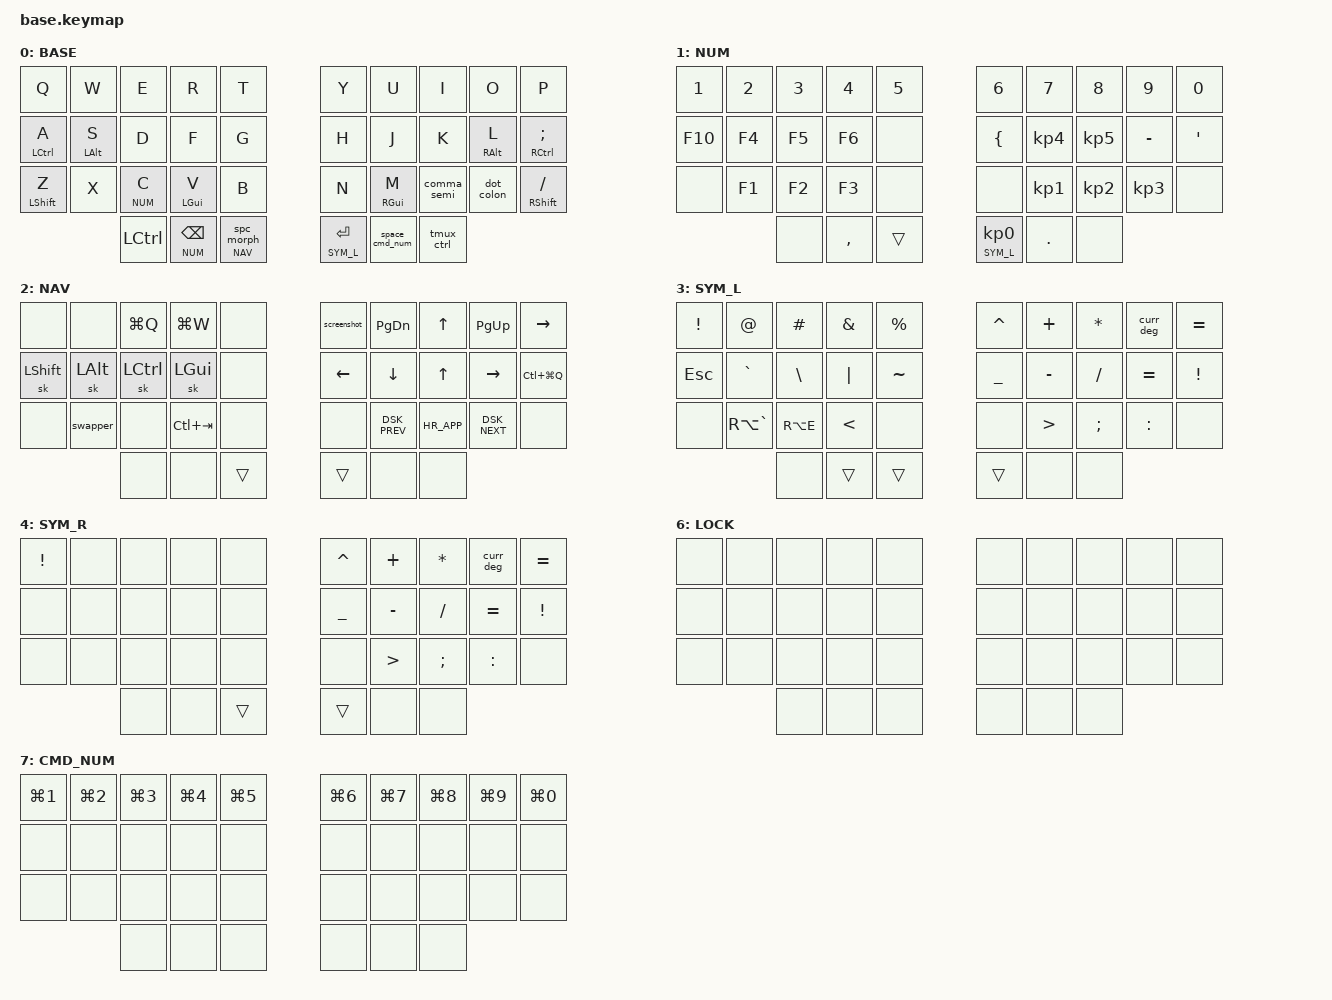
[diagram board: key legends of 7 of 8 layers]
#include <behaviors.dtsi>
#include <dt-bindings/zmk/keys.h>
#include <dt-bindings/zmk/outputs.h>

// ── LAYERS ────────────────────────────────────────────────────────────────────

#define BASE 0
#define NUM 1
#define NAV 2
#define SYM_L 3
#define SYM_R 4
#define ADJ 5
#define LOCKL 6
#define CMD_NUM 7

#define xxx &none
#define ___ &trans

// ── INCLUDES & BLUETOOTH ──────────────────────────────────────────────────────

#include "combos.dtsi"
#if WIRELESS
    #include <dt-bindings/zmk/bt.h>
    #define BTL1  &bt BT_CLR   &bt BT_SEL 2  &bt BT_SEL 1  &bt BT_SEL 0
    #define BTL2  xxx          &bt BT_SEL 4  &bt BT_SEL 3  &out OUT_TOG
#else
    #define BTL1  xxx   xxx   xxx   xxx
    #define BTL2  xxx   xxx   xxx   xxx
#endif

// ── TIMING ────────────────────────────────────────────────────────────────────

#define TAP_TERM_MS 200
#define QUICK_TAP_MS 125

// ── KEY SHORTCUTS ─────────────────────────────────────────────────────────────

#define deg RA(LS(N8))
#define HR_APP LG(LS(SPACE))
#define DSK_PREV LC(LEFT)
#define DSK_NEXT LC(RIGHT)

// ── KEY POSITIONS (for homerow mods) ──────────────────────────────────────────
//  ╭─────────────────────╮ ╭─────────────────────╮
//  │  00  01  02  03  04 │ │  05  06  07  08  09 │
//  │  10  11  12  13  14 │ │  15  16  17  18  19 │
//  │  20  21  22  23  24 │ │  25  26  27  28  29 │
//  ╰───────╮  30  31  32 │ │  33  34  35 ╭───────╯
//          ╰─────────────╯ ╰─────────────╯

#define LEFT_KEYS  0 1 2 3 4 10 11 12 13 14 20 21 22 23 24
#define RIGHT_KEYS 5 6 7 8 9 15 16 17 18 19 25 26 27 28 29
#define THUMBS     30 31 32 33 34 35

// ── GLOBAL BEHAVIOR OVERRIDES ─────────────────────────────────────────────────

&lt {
    flavor = "balanced";
    tapping-term-ms = <TAP_TERM_MS>;
    quick-tap-ms = <QUICK_TAP_MS>;
};

&sk {
    release-after-ms = <1000>;
    quick-release;
};

&sl {
    release-after-ms = <5000>;
};

&caps_word {
    continue-list = <UNDERSCORE MINUS BSPC N1 N2 N3 N4 N5 N6 N7 N8 N9 N0>;
};

// ── MAIN TREE ─────────────────────────────────────────────────────────────────

/ {
    behaviors {

        // ── HOMEROW MODS (timeless) ───────────────────────────────────────────
        // Only trigger hold when the *opposite* hand presses a key,
        // and only if there was an idle gap before the HRM key.

        hml: left_hand_positional_hold_tap {
            compatible = "zmk,behavior-hold-tap";
            label = "LEFT_POSITIONAL_HOLD_TAP";
            #binding-cells = <2>;
            flavor = "balanced";
            tapping-term-ms = <TAP_TERM_MS>;
            quick-tap-ms = <QUICK_TAP_MS>;
            require-prior-idle-ms = <100>;
            bindings = <&kp>, <&kp>;
            hold-trigger-key-positions = <RIGHT_KEYS THUMBS>;
            hold-trigger-on-release;
        };

        hmr: right_hand_positional_hold_tap {
            compatible = "zmk,behavior-hold-tap";
            label = "RIGHT_POSITIONAL_HOLD_TAP";
            #binding-cells = <2>;
            flavor = "balanced";
            tapping-term-ms = <TAP_TERM_MS>;
            quick-tap-ms = <QUICK_TAP_MS>;
            require-prior-idle-ms = <100>;
            bindings = <&kp>, <&kp>;
            hold-trigger-key-positions = <LEFT_KEYS THUMBS>;
            hold-trigger-on-release;
        };

        // ── TAP DANCES ────────────────────────────────────────────────────────

        curr_deg: tap_dance_curr_deg { // $ → € → °
            compatible = "zmk,behavior-tap-dance";
            label = "TAP_DANCE_curr_deg";
            #binding-cells = <0>;
            tapping-term-ms = <TAP_TERM_MS>;
            bindings = <&kp DLLR>, <&kp LA(N5)>, <&kp deg>;
        };
        screenshot: screenshot { // area selector → full-screen
            compatible = "zmk,behavior-tap-dance";
            label = "SCREENSHOT";
            #binding-cells = <0>;
            tapping-term-ms = <TAP_TERM_MS>;
            bindings = <&kp LG(LS(NUMBER_4))>, <&kp LG(LS(NUMBER_3))>;
        };
        tmux_ctrl: tmux_ctrl {
            compatible = "zmk,behavior-tap-dance";
            label = "TMUX_CTRL";
            #binding-cells = <0>;
            tapping-term-ms = <TAP_TERM_MS>;
            bindings = <&kp RCTRL>, <&tmux_num>;
        };
        space_cmd_num: space_cmd_num {
            compatible = "zmk,behavior-tap-dance";
            label = "SPACE_CMD_NUM";
            #binding-cells = <0>;
            tapping-term-ms = <TAP_TERM_MS>;
            bindings = <&kp SPACE>, <&mo CMD_NUM>;
        };

        // ── SMART SPACE (hold: layer | tap: space | shift+tap: ". " + sticky shift) ──

        spc_morph: spc_morph {
            compatible = "zmk,behavior-mod-morph";
            label = "SPC_MORPH";
            #binding-cells = <0>;
            bindings = <&kp SPACE>, <&dot_spc>;
            mods = <(MOD_LSFT)>;
        };
        lt_spc: lt_spc {
            compatible = "zmk,behavior-hold-tap";
            label = "LT_SPC";
            #binding-cells = <2>;
            tapping-term-ms = <TAP_TERM_MS>;
            quick-tap-ms = <QUICK_TAP_MS>;
            flavor = "balanced";
            bindings = <&mo>, <&spc_morph>;
        };

        // ── ALT-TAB SWAPPER (tri-state: Cmd+Tab) ────────────────────────────

        swapper: swapper {
            compatible = "zmk,behavior-tri-state";
            label = "SWAPPER";
            #binding-cells = <0>;
            bindings = <&kt LGUI>, <&kp TAB>, <&kt LGUI>;
            ignored-key-positions = <31>;
        };

        // ── MOD-MORPHS (shift changes symbol) ────────────────────────────────

        dot_colon: dot_colon { // . → :
            compatible = "zmk,behavior-mod-morph";
            label = "DOT_TO_COLON";
            #binding-cells = <0>;
            bindings = <&kp DOT>, <&kp COLON>;
            mods = <(MOD_LSFT|MOD_RSFT)>;
        };
        comma_semi: comma_semi { // , → ;
            compatible = "zmk,behavior-mod-morph";
            label = "COMMA_TO_SEMICOLON";
            #binding-cells = <0>;
            bindings = <&kp COMMA>, <&kp SEMICOLON>;
            mods = <(MOD_LSFT|MOD_RSFT)>;
        };
        single_to_doublequote: single_to_doublequote { // ' → "
            compatible = "zmk,behavior-mod-morph";
            label = "SINGLE_TO_DOUBLEQUOTE";
            #binding-cells = <0>;
            bindings = <&kp SINGLE_QUOTE>, <&kp DOUBLE_QUOTES>;
            mods = <(MOD_LSFT|MOD_RSFT)>;
        };
    };

    // ── MACROS ────────────────────────────────────────────────────────────────

    macros {
        // delete entire line: End → Cmd+Home → Backspace
        del_line: del_line {
            label = "ZMK_DEL_LINE";
            compatible = "zmk,behavior-macro";
            #binding-cells = <0>;
            bindings
                = <&macro_press &kp END>
                , <&macro_press &kp LGUI>
                , <&macro_tap &kp HOME>
                , <&macro_release &kp LGUI>
                , <&macro_tap &kp BSPC>
                ;
        };

        // sentence ending: types ". " then activates sticky shift
        dot_spc: dot_spc {
            label = "ZM_DOT_SPACE";
            compatible = "zmk,behavior-macro";
            #binding-cells = <0>;
            wait-ms = <0>;
            tap-ms = <5>;
            bindings = <&kp DOT &kp SPACE &sk LSHFT>;
        };

        // tmux window selection: send prefix, then enable NUM for one keypress
        tmux_num: tmux_num {
            label = "TMUX_NUM";
            compatible = "zmk,behavior-macro";
            #binding-cells = <0>;
            bindings = <&kp LC(A) &sl NUM>;
        };
    };

    // ── CONDITIONAL LAYERS ────────────────────────────────────────────────────
    // NAV + SYM_L → ADJ (hold both layer thumbs)

    conditional_layers {
        compatible = "zmk,conditional-layers";
        tri_layer {
            if-layers = <NAV SYM_L>;
            then-layer = <ADJ>;
        };
    };

    // ── KEYMAP ────────────────────────────────────────────────────────────────

    keymap {
        compatible = "zmk,keymap";

        default_layer {
            label = "BASE";
            bindings = <
             //╭──────────────┬──────────────┬──────────────┬──────────────┬──────────────╮     ╭──────────────┬──────────────┬──────────────┬──────────────┬──────────────╮
                &kp Q            &kp W          &kp E          &kp R         &kp T                 &kp Y          &kp U          &kp I          &kp O          &kp P
             //├──────────────┼──────────────┼──────────────┼──────────────┼──────────────┤     ├──────────────┼──────────────┼──────────────┼──────────────┼──────────────┤
                &hml LCTRL A    &hml LALT S    &kp D          &kp F           &kp G                 &kp H          &kp J          &kp K          &hmr RALT L  &hmr RCTRL SEMI
             //├──────────────┼──────────────┼──────────────┼──────────────┼──────────────┤     ├──────────────┼──────────────┼──────────────┼──────────────┼──────────────┤
                &hml LSHIFT Z    &kp X          &lt NUM C      &hml LGUI V    &kp B                &kp N            &hmr RGUI M  &comma_semi    &dot_colon     &hmr RSHIFT SLASH
             //╰──────────────┴──────────────┼──────────────┼──────────────┼──────────────┤     ├──────────────┼──────────────┼──────────────┼──────────────┴──────────────╯
                                              &kp LCTRL        &lt NUM BSPC   &lt_spc NAV 0        &lt SYM_L RET    &space_cmd_num &tmux_ctrl
             //                              ╰──────────────┴──────────────┴──────────────╯     ╰──────────────┴──────────────┴──────────────╯
            >;
        };

        num_layer {
            label = "NUM";
            bindings = <
             //╭──────────────┬──────────────┬──────────────┬──────────────┬──────────────╮     ╭──────────────┬──────────────┬──────────────┬──────────────┬──────────────╮
                &kp N1         &kp N2         &kp N3         &kp N4         &kp N5               &kp N6         &kp N7         &kp N8         &kp N9         &kp N0
             //├──────────────┼──────────────┼──────────────┼──────────────┼──────────────┤     ├──────────────┼──────────────┼──────────────┼──────────────┼──────────────┤
                &kp F10        &kp F4         &kp F5         &kp F6         xxx                  &kp LBRC       &kp KP_N4      &kp KP_N5      &kp MINUS      &kp SQT
             //├──────────────┼──────────────┼──────────────┼──────────────┼──────────────┤     ├──────────────┼──────────────┼──────────────┼──────────────┼──────────────┤
                xxx            &kp F1         &kp F2         &kp F3         xxx                  xxx            &kp KP_N1      &kp KP_N2      &kp KP_N3      xxx
             //╰──────────────┴──────────────┼──────────────┼──────────────┼──────────────┤     ├──────────────┼──────────────┼──────────────┼──────────────┴──────────────╯
                                              xxx            &kp COMMA      ___                  &lt SYM_L KP_N0 &kp DOT       xxx
             //                              ╰──────────────┴──────────────┴──────────────╯     ╰──────────────┴──────────────┴──────────────╯
            >;
        };

        nav_layer {
            label = "NAV";
            bindings = <
             //╭──────────────┬──────────────┬──────────────┬──────────────┬──────────────╮     ╭──────────────┬──────────────┬──────────────┬──────────────┬──────────────╮
                xxx            xxx            &kp LG(Q)      &kp LG(W)      xxx                  &screenshot      &kp PG_DN      &kp UP         &kp PG_UP      &kp RIGHT
             //├──────────────┼──────────────┼──────────────┼──────────────┼──────────────┤     ├──────────────┼──────────────┼──────────────┼──────────────┼──────────────┤
                &sk LSHFT      &sk LALT       &sk LCTRL      &sk LGUI       xxx                  &kp LEFT         &kp DOWN        &kp UP       &kp RIGHT      &kp LC(LG(Q))
             //├──────────────┼──────────────┼──────────────┼──────────────┼──────────────┤     ├──────────────┼──────────────┼──────────────┼──────────────┼──────────────┤
                xxx            &swapper       xxx            &kp LC(TAB)    xxx                  xxx              &kp DSK_PREV   &kp HR_APP     &kp DSK_NEXT   xxx
             //╰──────────────┴──────────────┼──────────────┼──────────────┼──────────────┤     ├──────────────┼──────────────┼──────────────┼──────────────┴──────────────╯
                                              xxx            xxx            ___                  ___            xxx            xxx
             //                              ╰──────────────┴──────────────┴──────────────╯     ╰──────────────┴──────────────┴──────────────╯
            >;
        };

        symbols_left { // activated by right thumb — symbols on both hands
            label = "SYM_L";
            bindings = <
             //╭──────────────┬──────────────┬──────────────┬──────────────┬──────────────╮     ╭──────────────┬──────────────┬──────────────┬──────────────┬──────────────╮
                &kp EXCL       &kp AT         &kp HASH       &kp AMPS       &kp PERCENT          &kp CARET      &kp PLUS       &kp ASTRK      &curr_deg      &kp EQUAL
             //├──────────────┼──────────────┼──────────────┼──────────────┼──────────────┤     ├──────────────┼──────────────┼──────────────┼──────────────┼──────────────┤
                &kp ESCAPE     &kp GRAVE      &kp BSLH       &kp PIPE       &kp TILDE            &kp UNDER      &kp MINUS      &kp SLASH      &kp EQUAL      &kp EXCL
             //├──────────────┼──────────────┼──────────────┼──────────────┼──────────────┤     ├──────────────┼──────────────┼──────────────┼──────────────┼──────────────┤
                xxx            &kp RA(GRAVE)  &kp RA(E)      &kp LT         xxx                  xxx            &kp GT         &kp SEMI       &kp COLON      xxx
             //╰──────────────┴──────────────┼──────────────┼──────────────┼──────────────┤     ├──────────────┼──────────────┼──────────────┼──────────────┴──────────────╯
                                              xxx            ___            ___                  ___            xxx            xxx
             //                              ╰──────────────┴──────────────┴──────────────╯     ╰──────────────┴──────────────┴──────────────╯
            >;
        };

        symbols_right { // activated by left thumb — right-hand symbols
            label = "SYM_R";
            bindings = <
             //╭──────────────┬──────────────┬──────────────┬──────────────┬──────────────╮     ╭──────────────┬──────────────┬──────────────┬──────────────┬──────────────╮
                &kp EXCL       xxx            xxx            xxx            xxx                  &kp CARET      &kp PLUS       &kp ASTRK      &curr_deg      &kp EQUAL
             //├──────────────┼──────────────┼──────────────┼──────────────┼──────────────┤     ├──────────────┼──────────────┼──────────────┼──────────────┼──────────────┤
                xxx            xxx            xxx            xxx            xxx                  &kp UNDER      &kp MINUS      &kp SLASH      &kp EQUAL      &kp EXCL
             //├──────────────┼──────────────┼──────────────┼──────────────┼──────────────┤     ├──────────────┼──────────────┼──────────────┼──────────────┼──────────────┤
                xxx            xxx            xxx            xxx            xxx                  xxx            &kp GT         &kp SEMI       &kp COLON      xxx
             //╰──────────────┴──────────────┼──────────────┼──────────────┼──────────────┤     ├──────────────┼──────────────┼──────────────┼──────────────┴──────────────╯
                                              xxx            xxx            ___                  ___            xxx            xxx
             //                              ╰──────────────┴──────────────┴──────────────╯     ╰──────────────┴──────────────┴──────────────╯
            >;
        };

        adj_layer { // tri-layer: SYM_L + SYM_R — system, media, bluetooth
            label = "ADJ";
            bindings = <
             //╭──────────────┬──────────────┬──────────────┬──────────────┬──────────────╮     ╭──────────────┬──────────────┬──────────────┬──────────────┬──────────────╮
                xxx              xxx            xxx            xxx            &bootloader          &bootloader    &kp C_PP       &kp C_NEXT     &kp C_PREV     xxx
             //├──────────────┼──────────────┼──────────────┼──────────────┼──────────────┤     ├──────────────┼──────────────┼──────────────┼──────────────┼──────────────┤
                BTL1                                                        &sys_reset           &sys_reset     &kp C_VOL_DN   &kp C_VOL_UP   &kp C_MUTE     xxx
             //├──────────────┼──────────────┼──────────────┼──────────────┼──────────────┤     ├──────────────┼──────────────┼──────────────┼──────────────┼──────────────┤
                BTL2                                                        xxx                  xxx            &kp C_BRI_DN   &kp C_BRI_UP   xxx            xxx
             //╰──────────────┴──────────────┼──────────────┼──────────────┼──────────────┤     ├──────────────┼──────────────┼──────────────┼──────────────┴──────────────╯
                                              xxx            xxx            xxx                  xxx            xxx            xxx
             //                              ╰──────────────┴──────────────┴──────────────╯     ╰──────────────┴──────────────┴──────────────╯
            >;
        };

        lock_layer {
            label = "LOCK";
            bindings = <
             //╭──────────────┬──────────────┬──────────────┬──────────────┬──────────────╮     ╭──────────────┬──────────────┬──────────────┬──────────────┬──────────────╮
                xxx            xxx            xxx            xxx            xxx                  xxx            xxx            xxx            xxx            xxx
             //├──────────────┼──────────────┼──────────────┼──────────────┼──────────────┤     ├──────────────┼──────────────┼──────────────┼──────────────┼──────────────┤
                xxx            xxx            xxx            xxx            xxx                  xxx            xxx            xxx            xxx            xxx
             //├──────────────┼──────────────┼──────────────┼──────────────┼──────────────┤     ├──────────────┼──────────────┼──────────────┼──────────────┼──────────────┤
                xxx            xxx            xxx            xxx            xxx                  xxx            xxx            xxx            xxx            xxx
             //╰──────────────┴──────────────┼──────────────┼──────────────┼──────────────┤     ├──────────────┼──────────────┼──────────────┼──────────────┴──────────────╯
                                              xxx            xxx            xxx                  xxx            xxx            xxx
             //                              ╰──────────────┴──────────────┴──────────────╯     ╰──────────────┴──────────────┴──────────────╯
            >;
        };

        cmd_num_layer {
            label = "CMD_NUM";
            bindings = <
             //╭──────────────┬──────────────┬──────────────┬──────────────┬──────────────╮     ╭──────────────┬──────────────┬──────────────┬──────────────┬──────────────╮
                &kp LG(N1)     &kp LG(N2)     &kp LG(N3)     &kp LG(N4)     &kp LG(N5)           &kp LG(N6)     &kp LG(N7)     &kp LG(N8)     &kp LG(N9)     &kp LG(N0)
             //├──────────────┼──────────────┼──────────────┼──────────────┼──────────────┤     ├──────────────┼──────────────┼──────────────┼──────────────┼──────────────┤
                xxx            xxx            xxx            xxx            xxx                  xxx            xxx            xxx            xxx            xxx
             //├──────────────┼──────────────┼──────────────┼──────────────┼──────────────┤     ├──────────────┼──────────────┼──────────────┼──────────────┼──────────────┤
                xxx            xxx            xxx            xxx            xxx                  xxx            xxx            xxx            xxx            xxx
             //╰──────────────┴──────────────┼──────────────┼──────────────┼──────────────┤     ├──────────────┼──────────────┼──────────────┴──────────────┴──────────────╯
                                              xxx            xxx            xxx                  xxx            xxx            xxx
             //                              ╰──────────────┴──────────────┴──────────────╯     ╰──────────────┴──────────────┴──────────────╯
            >;
        };

    };
};
